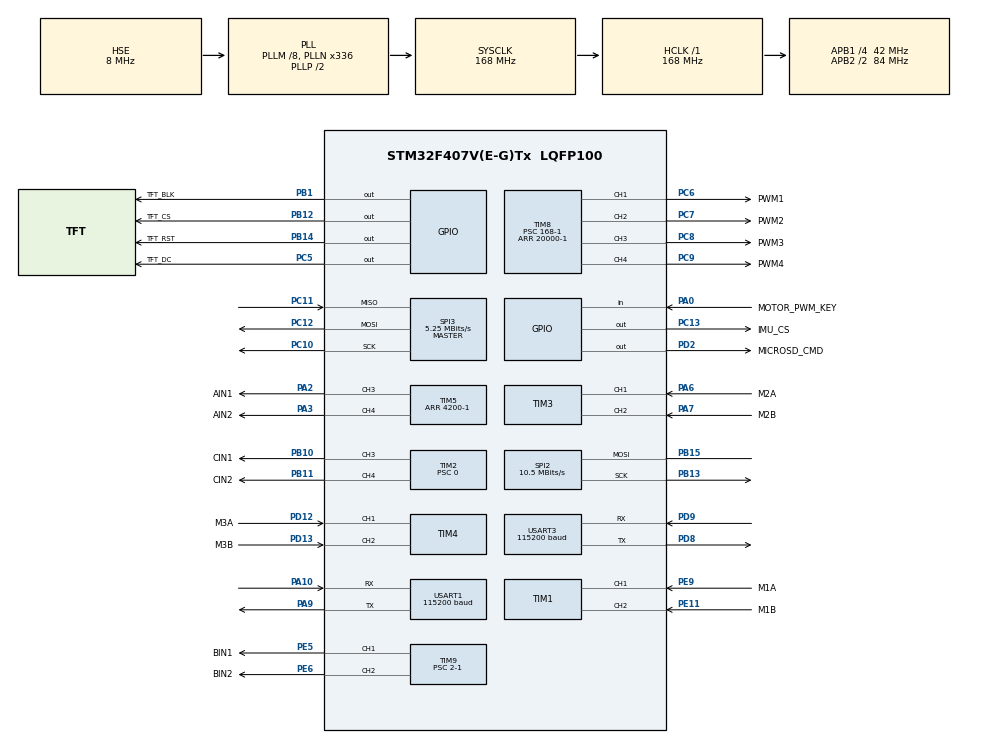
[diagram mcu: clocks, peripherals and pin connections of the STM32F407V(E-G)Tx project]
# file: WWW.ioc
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Dma.Request0=USART1_RX
Dma.Request1=USART3_RX
Dma.USART1_RX.0.Direction=DMA_PERIPH_TO_MEMORY
Dma.USART1_RX.0.FIFOMode=DMA_FIFOMODE_DISABLE
Dma.USART1_RX.0.Instance=DMA2_Stream2
Dma.USART1_RX.0.MemDataAlignment=DMA_MDATAALIGN_BYTE
Dma.USART1_RX.0.MemInc=DMA_MINC_ENABLE
Dma.USART1_RX.0.Mode=DMA_CIRCULAR
Dma.USART1_RX.0.PeriphDataAlignment=DMA_PDATAALIGN_BYTE
Dma.USART1_RX.0.PeriphInc=DMA_PINC_DISABLE
Dma.USART1_RX.0.Priority=DMA_PRIORITY_LOW
Dma.USART3_RX.1.Direction=DMA_PERIPH_TO_MEMORY
Dma.USART3_RX.1.FIFOMode=DMA_FIFOMODE_DISABLE
Dma.USART3_RX.1.Instance=DMA1_Stream1
Dma.USART3_RX.1.MemDataAlignment=DMA_MDATAALIGN_BYTE
Dma.USART3_RX.1.MemInc=DMA_MINC_ENABLE
Dma.USART3_RX.1.Mode=DMA_CIRCULAR
Dma.USART3_RX.1.PeriphDataAlignment=DMA_PDATAALIGN_BYTE
Dma.USART3_RX.1.PeriphInc=DMA_PINC_DISABLE
Dma.USART3_RX.1.Priority=DMA_PRIORITY_LOW
Mcu.Family=STM32F4
Mcu.Name=STM32F407V(E-G)Tx
Mcu.Package=LQFP100
NVIC.DMA2_Stream2_IRQn=true\:5\:0\:true\:false\:true\:false\:true\:true
NVIC.DMA1_Stream1_IRQn=true\:5\:0\:true\:false\:true\:false\:true\:true
NVIC.PriorityGroup=NVIC_PRIORITYGROUP_4
NVIC.TIM6_DAC_IRQn=true\:4\:0\:true\:false\:true\:true\:true\:true
NVIC.USART1_IRQn=true\:7\:0\:true\:false\:true\:true\:true\:true
NVIC.USART3_IRQn=true\:7\:0\:true\:false\:true\:true\:true\:true
PA0.GPIO_Label=MOTOR_PWM_KEY
PA0.GPIO_PuPd=GPIO_PULLDOWN
PA0.Signal=GPIO_Input
PA13.Mode=Serial_Wire
PA13.Signal=SYS_JTMS-SWDIO
PA14.Mode=Serial_Wire
PA14.Signal=SYS_JTCK-SWCLK
PA2.GPIO_Label=AIN1
PA2.Signal=S_TIM5_CH3
PA3.GPIO_Label=AIN2
PA3.Signal=S_TIM5_CH4
PA6.GPIO_Label=M2A
PA6.GPIO_PuPd=GPIO_PULLUP
PA6.Signal=S_TIM3_CH1
PA7.GPIO_Label=M2B
PA7.GPIO_PuPd=GPIO_PULLUP
PA7.Signal=S_TIM3_CH2
PB1.GPIO_Label=TFT_BLK
PB1.Signal=GPIO_Output
PB10.GPIO_Label=CIN1
PB10.Signal=S_TIM2_CH3
PB11.GPIO_Label=CIN2
PB11.Signal=S_TIM2_CH4
PB12.GPIO_Label=TFT_CS
PB12.GPIO_OutputLevel=GPIO_PIN_SET
PB12.Signal=GPIO_Output
PB13.Mode=Simplex_Bidirectional_Master
PB13.Signal=SPI2_SCK
PB14.GPIO_Label=TFT_RST
PB14.GPIO_OutputLevel=GPIO_PIN_SET
PB14.Signal=GPIO_Output
PB15.Mode=Simplex_Bidirectional_Master
PB15.Signal=SPI2_MOSI
PC13.GPIO_Label=IMU_CS
PC13.GPIO_OutputLevel=GPIO_PIN_SET
PC13.Signal=GPIO_Output
PC10.GPIO_PuPd=GPIO_PULLUP
PC10.Mode=Full_Duplex_Master
PC10.Signal=SPI3_SCK
PC11.GPIO_PuPd=GPIO_PULLUP
PC11.Mode=Full_Duplex_Master
PC11.Signal=SPI3_MISO
PC12.GPIO_PuPd=GPIO_PULLUP
PC12.Mode=Full_Duplex_Master
PC12.Signal=SPI3_MOSI
PC5.GPIO_Label=TFT_DC
PC5.Signal=GPIO_Output
PC6.GPIO_Label=PWM1
PC6.Signal=S_TIM8_CH1
PC7.GPIO_Label=PWM2
PC7.Signal=S_TIM8_CH2
PC8.GPIO_Label=PWM3
PC8.Signal=S_TIM8_CH3
PC9.GPIO_Label=PWM4
PC9.Signal=S_TIM8_CH4
PD12.GPIO_Label=M3A
PD12.GPIO_PuPd=GPIO_PULLUP
PD12.Signal=S_TIM4_CH1
PD13.GPIO_Label=M3B
PD13.GPIO_PuPd=GPIO_PULLUP
PD13.Signal=S_TIM4_CH2
PD2.GPIO_Label=MICROSD_CMD
PD2.GPIO_OutputLevel=GPIO_PIN_SET
PD2.GPIO_PuPd=GPIO_PULLUP
PD2.Signal=GPIO_Output
PD8.Mode=Asynchronous
PD8.Signal=USART3_TX
PD9.Mode=Asynchronous
PD9.Signal=USART3_RX
PA10.Mode=Asynchronous
PA10.Signal=USART1_RX
PA9.Mode=Asynchronous
PA9.Signal=USART1_TX
PE11.GPIO_Label=M1B
PE11.GPIO_PuPd=GPIO_PULLUP
PE11.Signal=S_TIM1_CH2
PE5.GPIO_Label=BIN1
PE5.Signal=S_TIM9_CH1
PE6.GPIO_Label=BIN2
PE6.Signal=S_TIM9_CH2
PE9.GPIO_Label=M1A
PE9.GPIO_PuPd=GPIO_PULLUP
PE9.Signal=S_TIM1_CH1
PH0-OSC_IN.Mode=HSE-External-Oscillator
PH0-OSC_IN.Signal=RCC_OSC_IN
PH1-OSC_OUT.Mode=HSE-External-Oscillator
PH1-OSC_OUT.Signal=RCC_OSC_OUT
ProjectManager.HeapSize=0x200
ProjectManager.StackSize=0x400
ProjectManager.TargetToolchain=CMake
RCC.48MHZClocksFreq_Value=48000000
RCC.AHBFreq_Value=168000000
RCC.APB1CLKDivider=RCC_HCLK_DIV4
RCC.APB1Freq_Value=42000000
RCC.APB1TimFreq_Value=84000000
RCC.APB2CLKDivider=RCC_HCLK_DIV2
RCC.APB2Freq_Value=84000000
RCC.APB2TimFreq_Value=168000000
RCC.CortexFreq_Value=168000000
RCC.HCLKFreq_Value=168000000
RCC.HSE_VALUE=8000000
RCC.HSI_VALUE=16000000
RCC.LSE_VALUE=32768
RCC.PLLM=8
RCC.PLLN=336
RCC.PLLQ=7
RCC.PLLSourceVirtual=RCC_PLLSOURCE_HSE
RCC.SYSCLKFreq_VALUE=168000000
RCC.SYSCLKSource=RCC_SYSCLKSOURCE_PLLCLK
RCC.VCOOutputFreq_Value=336000000
SH.S_TIM1_CH1.0=TIM1_CH1,Encoder_Interface
SH.S_TIM1_CH2.0=TIM1_CH2,Encoder_Interface
SH.S_TIM2_CH3.0=TIM2_CH3,PWM Generation3 CH3
SH.S_TIM2_CH4.0=TIM2_CH4,PWM Generation4 CH4
SH.S_TIM3_CH1.0=TIM3_CH1,Encoder_Interface
SH.S_TIM3_CH2.0=TIM3_CH2,Encoder_Interface
SH.S_TIM4_CH1.0=TIM4_CH1,Encoder_Interface
SH.S_TIM4_CH2.0=TIM4_CH2,Encoder_Interface
SH.S_TIM5_CH3.0=TIM5_CH3,PWM Generation3 CH3
SH.S_TIM5_CH4.0=TIM5_CH4,PWM Generation4 CH4
SH.S_TIM8_CH1.0=TIM8_CH1,PWM Generation1 CH1
SH.S_TIM8_CH2.0=TIM8_CH2,PWM Generation2 CH2
SH.S_TIM8_CH3.0=TIM8_CH3,PWM Generation3 CH3
SH.S_TIM8_CH4.0=TIM8_CH4,PWM Generation4 CH4
SH.S_TIM9_CH1.0=TIM9_CH1,PWM Generation1 CH1
SH.S_TIM9_CH2.0=TIM9_CH2,PWM Generation2 CH2
SPI2.BaudRatePrescaler=SPI_BAUDRATEPRESCALER_4
SPI2.CalculateBaudRate=10.5 MBits/s
SPI2.CLKPhase=SPI_PHASE_1EDGE
SPI2.CLKPolarity=SPI_POLARITY_LOW
SPI2.Direction=SPI_DIRECTION_1LINE
SPI2.Mode=SPI_MODE_MASTER
SPI2.VirtualNSS=VM_NSS
SPI2.VirtualType=VM_MASTER
SPI3.BaudRatePrescaler=SPI_BAUDRATEPRESCALER_8
SPI3.CalculateBaudRate=5.25 MBits/s
SPI3.CLKPhase=SPI_PHASE_2EDGE
SPI3.CLKPolarity=SPI_POLARITY_HIGH
SPI3.Direction=SPI_DIRECTION_2LINES
SPI3.Mode=SPI_MODE_MASTER
SPI3.VirtualNSS=VM_NSS
SPI3.VirtualType=VM_MASTER
SYS.Debug=SYS_DEBUG_SERIAL_WIRE
TIM1.EncoderMode=TIM_ENCODERMODE_TI12
TIM1.IC1Filter=4
TIM1.IC2Filter=4
TIM2.Channel-PWM\ Generation3\ CH3=TIM_CHANNEL_3
TIM2.Channel-PWM\ Generation4\ CH4=TIM_CHANNEL_4
TIM2.Period=4200-1
TIM2.Prescaler=0
TIM3.EncoderMode=TIM_ENCODERMODE_TI12
TIM3.IC1Filter=4
TIM3.IC2Filter=4
TIM4.EncoderMode=TIM_ENCODERMODE_TI12
TIM4.IC1Filter=4
TIM4.IC2Filter=4
TIM5.Channel-PWM\ Generation3\ CH3=TIM_CHANNEL_3
TIM5.Channel-PWM\ Generation4\ CH4=TIM_CHANNEL_4
TIM5.Period=4200-1
TIM6.Period=1000-1
TIM6.Prescaler=84-1
TIM8.Channel-PWM\ Generation1\ CH1=TIM_CHANNEL_1
TIM8.Channel-PWM\ Generation2\ CH2=TIM_CHANNEL_2
TIM8.Channel-PWM\ Generation3\ CH3=TIM_CHANNEL_3
TIM8.Channel-PWM\ Generation4\ CH4=TIM_CHANNEL_4
TIM8.Period=20000-1
TIM8.Prescaler=168-1
TIM9.Channel-PWM\ Generation1\ CH1=TIM_CHANNEL_1
TIM9.Channel-PWM\ Generation2\ CH2=TIM_CHANNEL_2
TIM9.Period=4200-1
TIM9.Prescaler=2-1
USART1.BaudRate=115200
USART1.VirtualMode=VM_ASYNC
USART3.BaudRate=115200
USART3.VirtualMode=VM_ASYNC
VP_TIM6_VS_ClockSourceINT.Mode=Enable_Timer
board=custom

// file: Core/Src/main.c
/* USER CODE BEGIN Header */
/**
  ******************************************************************************
  * @file           : main.c
  * @brief          : Main program body
  ******************************************************************************
  * @attention
  *
  * Copyright (c) 2026 STMicroelectronics.
  * All rights reserved.
  *
  * This software is licensed under terms that can be found in the LICENSE file
  * in the root directory of this software component.
  * If no LICENSE file comes with this software, it is provided AS-IS.
  *
  ******************************************************************************
  */
/* USER CODE END Header */
#include "main.h"

/* USER CODE BEGIN Includes */
#include "Robot.h"
#include "MotionDiag.h"
#include "servo.h"
/* USER CODE END Includes */

DMA_HandleTypeDef hdma_usart1_rx;
DMA_HandleTypeDef hdma_usart3_rx;

SPI_HandleTypeDef hspi2;
SPI_HandleTypeDef hspi3;

TIM_HandleTypeDef htim1;
TIM_HandleTypeDef htim2;
TIM_HandleTypeDef htim3;
TIM_HandleTypeDef htim4;
TIM_HandleTypeDef htim5;
TIM_HandleTypeDef htim6;
TIM_HandleTypeDef htim8;
TIM_HandleTypeDef htim9;

UART_HandleTypeDef huart1;
UART_HandleTypeDef huart3;

void SystemClock_Config(void);
static void MX_GPIO_Init(void);
static void MX_TIM1_Init(void);
static void MX_TIM2_Init(void);
static void MX_TIM3_Init(void);
static void MX_TIM4_Init(void);
static void MX_TIM5_Init(void);
static void MX_TIM8_Init(void);
static void MX_TIM9_Init(void);
static void MX_SPI2_Init(void);
static void MX_SPI3_Init(void);
static void MX_TIM6_Init(void);
static void MX_USART1_UART_Init(void);
static void MX_USART3_UART_Init(void);
static void MX_DMA_Init(void);

int main(void)
{

  /* MCU Configuration--------------------------------------------------------*/

  /* Reset of all peripherals, Initializes the Flash interface and the Systick. */
  HAL_Init();

  /* Configure the system clock */
  SystemClock_Config();

  /* Initialize all configured peripherals */
  MX_GPIO_Init();
  MX_DMA_Init();
  MX_TIM1_Init();
  MX_TIM2_Init();
  MX_TIM3_Init();
  MX_TIM4_Init();
  MX_TIM5_Init();
  MX_TIM8_Init();
  MX_TIM9_Init();
  MX_SPI2_Init();
  MX_SPI3_Init();
  MX_TIM6_Init();
  MX_USART1_UART_Init();
  MX_USART3_UART_Init();
  /* USER CODE BEGIN 2 */
  Robot_Init();
  /* USER CODE END 2 */

  /* Infinite loop */
  while (1)
  {

    /* USER CODE BEGIN 3 */
    Robot_Process();
  }
  /* USER CODE END 3 */
}

void SystemClock_Config(void)
{
  RCC_OscInitTypeDef RCC_OscInitStruct = {0};
  RCC_ClkInitTypeDef RCC_ClkInitStruct = {0};

  /** Configure the main internal regulator output voltage
  */
  __HAL_RCC_PWR_CLK_ENABLE();
  __HAL_PWR_VOLTAGESCALING_CONFIG(PWR_REGULATOR_VOLTAGE_SCALE1);

  /** Initializes the RCC Oscillators according to the specified parameters
  * in the RCC_OscInitTypeDef structure.
  */
  RCC_OscInitStruct.OscillatorType = RCC_OSCILLATORTYPE_HSE;
  RCC_OscInitStruct.HSEState = RCC_HSE_ON;
  RCC_OscInitStruct.PLL.PLLState = RCC_PLL_ON;
  RCC_OscInitStruct.PLL.PLLSource = RCC_PLLSOURCE_HSE;
  RCC_OscInitStruct.PLL.PLLM = 8;
  RCC_OscInitStruct.PLL.PLLN = 336;
  RCC_OscInitStruct.PLL.PLLP = RCC_PLLP_DIV2;
  RCC_OscInitStruct.PLL.PLLQ = 7;
  if (HAL_RCC_OscConfig(&RCC_OscInitStruct) != HAL_OK)
  {
    Error_Handler();
  }

  /** Initializes the CPU, AHB and APB buses clocks
  */
  RCC_ClkInitStruct.ClockType = RCC_CLOCKTYPE_HCLK|RCC_CLOCKTYPE_SYSCLK
                              |RCC_CLOCKTYPE_PCLK1|RCC_CLOCKTYPE_PCLK2;
  RCC_ClkInitStruct.SYSCLKSource = RCC_SYSCLKSOURCE_PLLCLK;
  RCC_ClkInitStruct.AHBCLKDivider = RCC_SYSCLK_DIV1;
  RCC_ClkInitStruct.APB1CLKDivider = RCC_HCLK_DIV4;
  RCC_ClkInitStruct.APB2CLKDivider = RCC_HCLK_DIV2;

  if (HAL_RCC_ClockConfig(&RCC_ClkInitStruct, FLASH_LATENCY_5) != HAL_OK)
  {
    Error_Handler();
  }
}

static void MX_SPI2_Init(void)
{

  /* SPI2 parameter configuration*/
  hspi2.Instance = SPI2;
  hspi2.Init.Mode = SPI_MODE_MASTER;
  hspi2.Init.Direction = SPI_DIRECTION_1LINE;
  hspi2.Init.DataSize = SPI_DATASIZE_8BIT;
  hspi2.Init.CLKPolarity = SPI_POLARITY_LOW;
  hspi2.Init.CLKPhase = SPI_PHASE_1EDGE;
  hspi2.Init.NSS = SPI_NSS_SOFT;
  hspi2.Init.BaudRatePrescaler = SPI_BAUDRATEPRESCALER_4;
  hspi2.Init.FirstBit = SPI_FIRSTBIT_MSB;
  hspi2.Init.TIMode = SPI_TIMODE_DISABLE;
  hspi2.Init.CRCCalculation = SPI_CRCCALCULATION_DISABLE;
  hspi2.Init.CRCPolynomial = 10;
  if (HAL_SPI_Init(&hspi2) != HAL_OK)
  {
    Error_Handler();
  }

}

static void MX_TIM1_Init(void)
{

  TIM_Encoder_InitTypeDef sConfig = {0};
  TIM_MasterConfigTypeDef sMasterConfig = {0};

  htim1.Instance = TIM1;
  htim1.Init.Prescaler = 0;
  htim1.Init.CounterMode = TIM_COUNTERMODE_UP;
  htim1.Init.Period = 65535;
  htim1.Init.ClockDivision = TIM_CLOCKDIVISION_DIV1;
  htim1.Init.RepetitionCounter = 0;
  htim1.Init.AutoReloadPreload = TIM_AUTORELOAD_PRELOAD_DISABLE;
  sConfig.EncoderMode = TIM_ENCODERMODE_TI12;
  sConfig.IC1Polarity = TIM_ICPOLARITY_RISING;
  sConfig.IC1Selection = TIM_ICSELECTION_DIRECTTI;
  sConfig.IC1Prescaler = TIM_ICPSC_DIV1;
  sConfig.IC1Filter = 4;
  sConfig.IC2Polarity = TIM_ICPOLARITY_RISING;
  sConfig.IC2Selection = TIM_ICSELECTION_DIRECTTI;
  sConfig.IC2Prescaler = TIM_ICPSC_DIV1;
  sConfig.IC2Filter = 4;
  if (HAL_TIM_Encoder_Init(&htim1, &sConfig) != HAL_OK)
  {
    Error_Handler();
  }
  sMasterConfig.MasterOutputTrigger = TIM_TRGO_RESET;
  sMasterConfig.MasterSlaveMode = TIM_MASTERSLAVEMODE_DISABLE;
  if (HAL_TIMEx_MasterConfigSynchronization(&htim1, &sMasterConfig) != HAL_OK)
  {
    Error_Handler();
  }

}

static void MX_TIM2_Init(void)
{

  TIM_MasterConfigTypeDef sMasterConfig = {0};
  TIM_OC_InitTypeDef sConfigOC = {0};

  htim2.Instance = TIM2;
  htim2.Init.Prescaler = 0;
  htim2.Init.CounterMode = TIM_COUNTERMODE_UP;
  htim2.Init.Period = 4200-1;
  htim2.Init.ClockDivision = TIM_CLOCKDIVISION_DIV1;
  htim2.Init.AutoReloadPreload = TIM_AUTORELOAD_PRELOAD_DISABLE;
  if (HAL_TIM_PWM_Init(&htim2) != HAL_OK)
  {
    Error_Handler();
  }
  sMasterConfig.MasterOutputTrigger = TIM_TRGO_RESET;
  sMasterConfig.MasterSlaveMode = TIM_MASTERSLAVEMODE_DISABLE;
  if (HAL_TIMEx_MasterConfigSynchronization(&htim2, &sMasterConfig) != HAL_OK)
  {
    Error_Handler();
  }
  sConfigOC.OCMode = TIM_OCMODE_PWM1;
  sConfigOC.Pulse = 0;
  sConfigOC.OCPolarity = TIM_OCPOLARITY_HIGH;
  sConfigOC.OCFastMode = TIM_OCFAST_DISABLE;
  if (HAL_TIM_PWM_ConfigChannel(&htim2, &sConfigOC, TIM_CHANNEL_3) != HAL_OK)
  {
    Error_Handler();
  }
  if (HAL_TIM_PWM_ConfigChannel(&htim2, &sConfigOC, TIM_CHANNEL_4) != HAL_OK)
  {
    Error_Handler();
  }
  HAL_TIM_MspPostInit(&htim2);

}

static void MX_TIM3_Init(void)
{

  TIM_Encoder_InitTypeDef sConfig = {0};
  TIM_MasterConfigTypeDef sMasterConfig = {0};

  htim3.Instance = TIM3;
  htim3.Init.Prescaler = 0;
  htim3.Init.CounterMode = TIM_COUNTERMODE_UP;
  htim3.Init.Period = 65535;
  htim3.Init.ClockDivision = TIM_CLOCKDIVISION_DIV1;
  htim3.Init.AutoReloadPreload = TIM_AUTORELOAD_PRELOAD_DISABLE;
  sConfig.EncoderMode = TIM_ENCODERMODE_TI12;
  sConfig.IC1Polarity = TIM_ICPOLARITY_RISING;
  sConfig.IC1Selection = TIM_ICSELECTION_DIRECTTI;
  sConfig.IC1Prescaler = TIM_ICPSC_DIV1;
  sConfig.IC1Filter = 4;
  sConfig.IC2Polarity = TIM_ICPOLARITY_RISING;
  sConfig.IC2Selection = TIM_ICSELECTION_DIRECTTI;
  sConfig.IC2Prescaler = TIM_ICPSC_DIV1;
  sConfig.IC2Filter = 4;
  if (HAL_TIM_Encoder_Init(&htim3, &sConfig) != HAL_OK)
  {
    Error_Handler();
  }
  sMasterConfig.MasterOutputTrigger = TIM_TRGO_RESET;
  sMasterConfig.MasterSlaveMode = TIM_MASTERSLAVEMODE_DISABLE;
  if (HAL_TIMEx_MasterConfigSynchronization(&htim3, &sMasterConfig) != HAL_OK)
  {
    Error_Handler();
  }

}

static void MX_TIM4_Init(void)
{

  TIM_Encoder_InitTypeDef sConfig = {0};
  TIM_MasterConfigTypeDef sMasterConfig = {0};

  htim4.Instance = TIM4;
  htim4.Init.Prescaler = 0;
  htim4.Init.CounterMode = TIM_COUNTERMODE_UP;
  htim4.Init.Period = 65535;
  htim4.Init.ClockDivision = TIM_CLOCKDIVISION_DIV1;
  htim4.Init.AutoReloadPreload = TIM_AUTORELOAD_PRELOAD_DISABLE;
  sConfig.EncoderMode = TIM_ENCODERMODE_TI12;
  sConfig.IC1Polarity = TIM_ICPOLARITY_RISING;
  sConfig.IC1Selection = TIM_ICSELECTION_DIRECTTI;
  sConfig.IC1Prescaler = TIM_ICPSC_DIV1;
  sConfig.IC1Filter = 4;
  sConfig.IC2Polarity = TIM_ICPOLARITY_RISING;
  sConfig.IC2Selection = TIM_ICSELECTION_DIRECTTI;
  sConfig.IC2Prescaler = TIM_ICPSC_DIV1;
  sConfig.IC2Filter = 4;
  if (HAL_TIM_Encoder_Init(&htim4, &sConfig) != HAL_OK)
  {
    Error_Handler();
  }
  sMasterConfig.MasterOutputTrigger = TIM_TRGO_RESET;
  sMasterConfig.MasterSlaveMode = TIM_MASTERSLAVEMODE_DISABLE;
  if (HAL_TIMEx_MasterConfigSynchronization(&htim4, &sMasterConfig) != HAL_OK)
  {
    Error_Handler();
  }

}

static void MX_TIM5_Init(void)
{

  TIM_MasterConfigTypeDef sMasterConfig = {0};
  TIM_OC_InitTypeDef sConfigOC = {0};

  htim5.Instance = TIM5;
  htim5.Init.Prescaler = 0;
  htim5.Init.CounterMode = TIM_COUNTERMODE_UP;
  htim5.Init.Period = 4200-1;
  htim5.Init.ClockDivision = TIM_CLOCKDIVISION_DIV1;
  htim5.Init.AutoReloadPreload = TIM_AUTORELOAD_PRELOAD_DISABLE;
  if (HAL_TIM_PWM_Init(&htim5) != HAL_OK)
  {
    Error_Handler();
  }
  sMasterConfig.MasterOutputTrigger = TIM_TRGO_RESET;
  sMasterConfig.MasterSlaveMode = TIM_MASTERSLAVEMODE_DISABLE;
  if (HAL_TIMEx_MasterConfigSynchronization(&htim5, &sMasterConfig) != HAL_OK)
  {
    Error_Handler();
  }
  sConfigOC.OCMode = TIM_OCMODE_PWM1;
  sConfigOC.Pulse = 0;
  sConfigOC.OCPolarity = TIM_OCPOLARITY_HIGH;
  sConfigOC.OCFastMode = TIM_OCFAST_DISABLE;
  if (HAL_TIM_PWM_ConfigChannel(&htim5, &sConfigOC, TIM_CHANNEL_3) != HAL_OK)
  {
    Error_Handler();
  }
  if (HAL_TIM_PWM_ConfigChannel(&htim5, &sConfigOC, TIM_CHANNEL_4) != HAL_OK)
  {
    Error_Handler();
  }
  HAL_TIM_MspPostInit(&htim5);

}

static void MX_TIM6_Init(void)
{

  TIM_MasterConfigTypeDef sMasterConfig = {0};

  htim6.Instance = TIM6;
  htim6.Init.Prescaler = 84-1;
  htim6.Init.CounterMode = TIM_COUNTERMODE_UP;
  htim6.Init.Period = 1000-1;
  htim6.Init.AutoReloadPreload = TIM_AUTORELOAD_PRELOAD_DISABLE;
  if (HAL_TIM_Base_Init(&htim6) != HAL_OK)
  {
    Error_Handler();
  }
  sMasterConfig.MasterOutputTrigger = TIM_TRGO_RESET;
  sMasterConfig.MasterSlaveMode = TIM_MASTERSLAVEMODE_DISABLE;
  if (HAL_TIMEx_MasterConfigSynchronization(&htim6, &sMasterConfig) != HAL_OK)
  {
    Error_Handler();
  }

}

static void MX_TIM8_Init(void)
{

  TIM_MasterConfigTypeDef sMasterConfig = {0};
  TIM_OC_InitTypeDef sConfigOC = {0};
  TIM_BreakDeadTimeConfigTypeDef sBreakDeadTimeConfig = {0};

  htim8.Instance = TIM8;
  htim8.Init.Prescaler = 168-1;
  htim8.Init.CounterMode = TIM_COUNTERMODE_UP;
  htim8.Init.Period = 20000-1;
  htim8.Init.ClockDivision = TIM_CLOCKDIVISION_DIV1;
  htim8.Init.RepetitionCounter = 0;
  htim8.Init.AutoReloadPreload = TIM_AUTORELOAD_PRELOAD_DISABLE;
  if (HAL_TIM_PWM_Init(&htim8) != HAL_OK)
  {
    Error_Handler();
  }
  sMasterConfig.MasterOutputTrigger = TIM_TRGO_RESET;
  sMasterConfig.MasterSlaveMode = TIM_MASTERSLAVEMODE_DISABLE;
  if (HAL_TIMEx_MasterConfigSynchronization(&htim8, &sMasterConfig) != HAL_OK)
  {
    Error_Handler();
  }
  sConfigOC.OCMode = TIM_OCMODE_PWM1;
  sConfigOC.Pulse = 0;
  sConfigOC.OCPolarity = TIM_OCPOLARITY_HIGH;
  sConfigOC.OCNPolarity = TIM_OCNPOLARITY_HIGH;
  sConfigOC.OCFastMode = TIM_OCFAST_DISABLE;
  sConfigOC.OCIdleState = TIM_OCIDLESTATE_RESET;
  sConfigOC.OCNIdleState = TIM_OCNIDLESTATE_RESET;
  if (HAL_TIM_PWM_ConfigChannel(&htim8, &sConfigOC, TIM_CHANNEL_1) != HAL_OK)
  {
    Error_Handler();
  }
  if (HAL_TIM_PWM_ConfigChannel(&htim8, &sConfigOC, TIM_CHANNEL_2) != HAL_OK)
  {
    Error_Handler();
  }
  if (HAL_TIM_PWM_ConfigChannel(&htim8, &sConfigOC, TIM_CHANNEL_3) != HAL_OK)
  {
    Error_Handler();
  }
  if (HAL_TIM_PWM_ConfigChannel(&htim8, &sConfigOC, TIM_CHANNEL_4) != HAL_OK)
  {
    Error_Handler();
  }
  sBreakDeadTimeConfig.OffStateRunMode = TIM_OSSR_DISABLE;
  sBreakDeadTimeConfig.OffStateIDLEMode = TIM_OSSI_DISABLE;
  sBreakDeadTimeConfig.LockLevel = TIM_LOCKLEVEL_OFF;
  sBreakDeadTimeConfig.DeadTime = 0;
  sBreakDeadTimeConfig.BreakState = TIM_BREAK_DISABLE;
  sBreakDeadTimeConfig.BreakPolarity = TIM_BREAKPOLARITY_HIGH;
  sBreakDeadTimeConfig.AutomaticOutput = TIM_AUTOMATICOUTPUT_DISABLE;
  if (HAL_TIMEx_ConfigBreakDeadTime(&htim8, &sBreakDeadTimeConfig) != HAL_OK)
  {
    Error_Handler();
  }
  HAL_TIM_MspPostInit(&htim8);

}

static void MX_TIM9_Init(void)
{

  TIM_OC_InitTypeDef sConfigOC = {0};

  htim9.Instance = TIM9;
  htim9.Init.Prescaler = 2-1;
  htim9.Init.CounterMode = TIM_COUNTERMODE_UP;
  htim9.Init.Period = 4200-1;
  htim9.Init.ClockDivision = TIM_CLOCKDIVISION_DIV1;
  htim9.Init.AutoReloadPreload = TIM_AUTORELOAD_PRELOAD_DISABLE;
  if (HAL_TIM_PWM_Init(&htim9) != HAL_OK)
  {
    Error_Handler();
  }
  sConfigOC.OCMode = TIM_OCMODE_PWM1;
  sConfigOC.Pulse = 0;
  sConfigOC.OCPolarity = TIM_OCPOLARITY_HIGH;
  sConfigOC.OCFastMode = TIM_OCFAST_DISABLE;
  if (HAL_TIM_PWM_ConfigChannel(&htim9, &sConfigOC, TIM_CHANNEL_1) != HAL_OK)
  {
    Error_Handler();
  }
  if (HAL_TIM_PWM_ConfigChannel(&htim9, &sConfigOC, TIM_CHANNEL_2) != HAL_OK)
  {
    Error_Handler();
  }
  HAL_TIM_MspPostInit(&htim9);

}

static void MX_USART1_UART_Init(void)
{

  huart1.Instance = USART1;
  huart1.Init.BaudRate = 115200U;
  huart1.Init.WordLength = UART_WORDLENGTH_8B;
  huart1.Init.StopBits = UART_STOPBITS_1;
  huart1.Init.Parity = UART_PARITY_NONE;
  huart1.Init.Mode = UART_MODE_TX_RX;
  huart1.Init.HwFlowCtl = UART_HWCONTROL_NONE;
  huart1.Init.OverSampling = UART_OVERSAMPLING_16;
  if (HAL_UART_Init(&huart1) != HAL_OK)
  {
    Error_Handler();
  }

}

static void MX_USART3_UART_Init(void)
{
  huart3.Instance = USART3;
  huart3.Init.BaudRate = 115200U;
  huart3.Init.WordLength = UART_WORDLENGTH_8B;
  huart3.Init.StopBits = UART_STOPBITS_1;
  huart3.Init.Parity = UART_PARITY_NONE;
  huart3.Init.Mode = UART_MODE_TX_RX;
  huart3.Init.HwFlowCtl = UART_HWCONTROL_NONE;
  huart3.Init.OverSampling = UART_OVERSAMPLING_16;
  if (HAL_UART_Init(&huart3) != HAL_OK)
  {
    Error_Handler();
  }
}

static void MX_SPI3_Init(void)
{

  /* SPI3 parameter configuration*/
  hspi3.Instance = SPI3;
  hspi3.Init.Mode = SPI_MODE_MASTER;
  hspi3.Init.Direction = SPI_DIRECTION_2LINES;
  hspi3.Init.DataSize = SPI_DATASIZE_8BIT;
  hspi3.Init.CLKPolarity = SPI_POLARITY_HIGH;
  hspi3.Init.CLKPhase = SPI_PHASE_2EDGE;
  hspi3.Init.NSS = SPI_NSS_SOFT;
  hspi3.Init.BaudRatePrescaler = SPI_BAUDRATEPRESCALER_8;
  hspi3.Init.FirstBit = SPI_FIRSTBIT_MSB;
  hspi3.Init.TIMode = SPI_TIMODE_DISABLE;
  hspi3.Init.CRCCalculation = SPI_CRCCALCULATION_DISABLE;
  hspi3.Init.CRCPolynomial = 10;
  if (HAL_SPI_Init(&hspi3) != HAL_OK)
  {
    Error_Handler();
  }

}

static void MX_DMA_Init(void)
{
  __HAL_RCC_DMA1_CLK_ENABLE();
  __HAL_RCC_DMA2_CLK_ENABLE();

  HAL_NVIC_SetPriority(DMA1_Stream1_IRQn, 5, 0);
  HAL_NVIC_EnableIRQ(DMA1_Stream1_IRQn);

  HAL_NVIC_SetPriority(DMA2_Stream2_IRQn, 5, 0);
  HAL_NVIC_EnableIRQ(DMA2_Stream2_IRQn);
}

static void MX_GPIO_Init(void)
{
  GPIO_InitTypeDef GPIO_InitStruct = {0};

  /* GPIO Ports Clock Enable */
  __HAL_RCC_GPIOE_CLK_ENABLE();
  __HAL_RCC_GPIOH_CLK_ENABLE();
  __HAL_RCC_GPIOA_CLK_ENABLE();
  __HAL_RCC_GPIOC_CLK_ENABLE();
  __HAL_RCC_GPIOB_CLK_ENABLE();
  __HAL_RCC_GPIOD_CLK_ENABLE();

  /*Configure GPIO pin Output Level */
  HAL_GPIO_WritePin(TFT_DC_GPIO_Port, TFT_DC_Pin, GPIO_PIN_RESET);

  /*Configure GPIO pin Output Level */
  HAL_GPIO_WritePin(TFT_BLK_GPIO_Port, TFT_BLK_Pin, GPIO_PIN_RESET);

  /*Configure GPIO pin Output Level */
  HAL_GPIO_WritePin(TFT_RST_GPIO_Port, TFT_RST_Pin, GPIO_PIN_SET);

  /*Configure GPIO pin Output Level */
  HAL_GPIO_WritePin(TFT_CS_GPIO_Port, TFT_CS_Pin, GPIO_PIN_SET);

  /*Configure GPIO pin Output Level */
  HAL_GPIO_WritePin(IMU_CS_GPIO_Port, IMU_CS_Pin, GPIO_PIN_SET);

  /* Keep the unused onboard MicroSD SDIO command line inactive. */
  HAL_GPIO_WritePin(MICROSD_CMD_GPIO_Port, MICROSD_CMD_Pin, GPIO_PIN_SET);

  /*Configure GPIO pin : TFT_DC_Pin */
  GPIO_InitStruct.Pin = TFT_DC_Pin;
  GPIO_InitStruct.Mode = GPIO_MODE_OUTPUT_PP;
  GPIO_InitStruct.Pull = GPIO_NOPULL;
  GPIO_InitStruct.Speed = GPIO_SPEED_FREQ_LOW;
  HAL_GPIO_Init(TFT_DC_GPIO_Port, &GPIO_InitStruct);

  /*Configure GPIO pins : TFT_BLK_Pin TFT_RST_Pin TFT_CS_Pin */
  GPIO_InitStruct.Pin = TFT_BLK_Pin|TFT_RST_Pin|TFT_CS_Pin;
  GPIO_InitStruct.Mode = GPIO_MODE_OUTPUT_PP;
  GPIO_InitStruct.Pull = GPIO_NOPULL;
  GPIO_InitStruct.Speed = GPIO_SPEED_FREQ_LOW;
  HAL_GPIO_Init(GPIOB, &GPIO_InitStruct);

  /*Configure GPIO pin : IMU_CS_Pin */
  GPIO_InitStruct.Pin = IMU_CS_Pin;
  GPIO_InitStruct.Mode = GPIO_MODE_OUTPUT_PP;
  GPIO_InitStruct.Pull = GPIO_NOPULL;
  GPIO_InitStruct.Speed = GPIO_SPEED_FREQ_HIGH;
  HAL_GPIO_Init(IMU_CS_GPIO_Port, &GPIO_InitStruct);

  /*Configure GPIO pin : MICROSD_CMD_Pin */
  GPIO_InitStruct.Pin = MICROSD_CMD_Pin;
  GPIO_InitStruct.Mode = GPIO_MODE_OUTPUT_PP;
  GPIO_InitStruct.Pull = GPIO_PULLUP;
  GPIO_InitStruct.Speed = GPIO_SPEED_FREQ_HIGH;
  HAL_GPIO_Init(MICROSD_CMD_GPIO_Port, &GPIO_InitStruct);

  /*Configure GPIO pin : MOTOR_PWM_KEY_Pin */
  GPIO_InitStruct.Pin = MOTOR_PWM_KEY_Pin;
  GPIO_InitStruct.Mode = GPIO_MODE_INPUT;
  GPIO_InitStruct.Pull = GPIO_PULLDOWN;
  HAL_GPIO_Init(MOTOR_PWM_KEY_GPIO_Port, &GPIO_InitStruct);

}

void Error_Handler(void)
{
#if APP_ENABLE_MOTION_DEBUG_TASK
  MotionDiag_Error((uint32_t)__builtin_return_address(0));
#endif
  __disable_irq();
  while (1)
  {
  }
}
